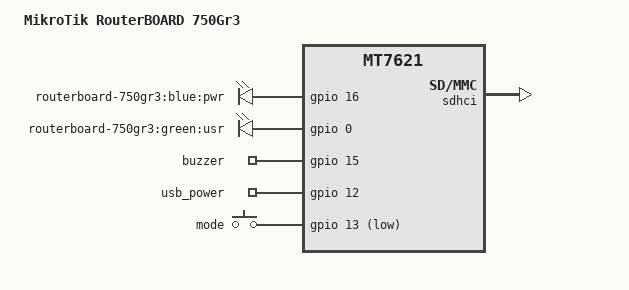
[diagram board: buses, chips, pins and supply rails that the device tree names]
// SPDX-License-Identifier: GPL-2.0-or-later OR MIT
/dts-v1/;

#include "mt7621_mikrotik.dtsi"

/ {
	compatible = "mikrotik,routerboard-750gr3", "mediatek,mt7621-soc";
	model = "MikroTik RouterBOARD 750Gr3";

	aliases {
		led-boot = &led_usr;
		led-failsafe = &led_usr;
		led-running = &led_usr;
		led-upgrade = &led_usr;
	};

	leds {
		compatible = "gpio-leds";

		pwr {
			label = "routerboard-750gr3:blue:pwr";
			gpios = <&gpio 16 GPIO_ACTIVE_HIGH>;
			default-state = "on";
		};

		led_usr: usr {
			label = "routerboard-750gr3:green:usr";
			gpios = <&gpio 0 GPIO_ACTIVE_HIGH>;
		};
	};

	gpio_export {
		compatible = "gpio-export";
		#size-cells = <0>;

		buzzer {
			/* Beeper requires PWM for frequency selection */
			gpio-export,name = "buzzer";
			gpio-export,output = <0>;
			gpios = <&gpio 15 GPIO_ACTIVE_HIGH>;
		};

		usb_power {
			gpio-export,name = "usb_power";
			gpio-export,output = <1>;
			gpios = <&gpio 12 GPIO_ACTIVE_HIGH>;
		};
	};
};

&keys {
	mode {
		label = "mode";
		gpios = <&gpio 13 GPIO_ACTIVE_LOW>;
		linux,code = <BTN_0>;
	};
};

&partitions {
	partition@40000 {
		compatible = "mikrotik,minor";
		label = "firmware";
		reg = <0x040000 0xfc0000>;
	};
};

&switch0 {
	ports {
		port@0 {
			status = "okay";
			label = "wan";
		};

		port@1 {
			status = "okay";
			label = "lan2";
		};

		port@2 {
			status = "okay";
			label = "lan3";
		};

		port@3 {
			status = "okay";
			label = "lan4";
		};

		port@4 {
			status = "okay";
			label = "lan5";
		};
	};
};

&state_default {
	gpio {
		/* via gpio7 (uart3 group) the PoE status can be read */
		groups = "uart2", "uart3", "jtag", "wdt";
		function = "gpio";
	};
};

&sdhci {
	status = "okay";
};
